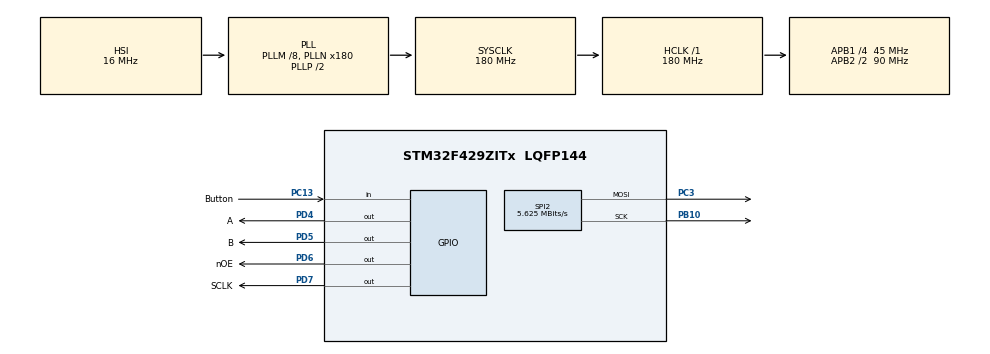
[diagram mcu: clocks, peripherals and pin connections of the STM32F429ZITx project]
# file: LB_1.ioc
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Mcu.Family=STM32F4
Mcu.Name=STM32F429ZITx
Mcu.Package=LQFP144
NVIC.PriorityGroup=NVIC_PRIORITYGROUP_4
NVIC.RCC_IRQn=true\:0\:0\:false\:false\:true\:true\:false\:true
NVIC.TIM1_UP_TIM10_IRQn=true\:0\:0\:false\:false\:true\:true\:true\:true
NVIC.TIM2_IRQn=true\:0\:0\:false\:false\:true\:true\:true\:true
PB10.Mode=TX_Only_Simplex_Unidirect_Master
PB10.Signal=SPI2_SCK
PC13.GPIO_Label=Button
PC13.Signal=GPIO_Input
PC14/OSC32_IN.Mode=LSE-External-Oscillator
PC14/OSC32_IN.Signal=RCC_OSC32_IN
PC15/OSC32_OUT.Mode=LSE-External-Oscillator
PC15/OSC32_OUT.Signal=RCC_OSC32_OUT
PC3.Mode=TX_Only_Simplex_Unidirect_Master
PC3.Signal=SPI2_MOSI
PD4.GPIO_Label=A
PD4.Signal=GPIO_Output
PD5.GPIO_Label=B
PD5.Signal=GPIO_Output
PD6.GPIO_Label=nOE
PD6.Signal=GPIO_Output
PD7.GPIO_Label=SCLK
PD7.Signal=GPIO_Output
PH0/OSC_IN.Mode=HSE-External-Oscillator
PH0/OSC_IN.Signal=RCC_OSC_IN
PH1/OSC_OUT.Mode=HSE-External-Oscillator
PH1/OSC_OUT.Signal=RCC_OSC_OUT
ProjectManager.HeapSize=0x200
ProjectManager.StackSize=0x400
ProjectManager.TargetToolchain=STM32CubeIDE
RCC.48MHZClocksFreq_Value=90000000
RCC.AHBFreq_Value=180000000
RCC.APB1CLKDivider=RCC_HCLK_DIV4
RCC.APB1Freq_Value=45000000
RCC.APB1TimFreq_Value=90000000
RCC.APB2CLKDivider=RCC_HCLK_DIV2
RCC.APB2Freq_Value=90000000
RCC.APB2TimFreq_Value=180000000
RCC.CortexFreq_Value=180000000
RCC.HCLKFreq_Value=180000000
RCC.HSE_VALUE=25000000
RCC.HSI_VALUE=16000000
RCC.PLLM=8
RCC.PLLN=180
RCC.SYSCLKFreq_VALUE=180000000
RCC.SYSCLKSource=RCC_SYSCLKSOURCE_PLLCLK
RCC.VCOOutputFreq_Value=360000000
SPI2.BaudRatePrescaler=SPI_BAUDRATEPRESCALER_8
SPI2.CalculateBaudRate=5.625 MBits/s
SPI2.Direction=SPI_DIRECTION_2LINES
SPI2.Mode=SPI_MODE_MASTER
SPI2.VirtualType=VM_MASTER
TIM1.Period=1000
TIM1.Prescaler=1000
TIM2.Period=1000
TIM2.Prescaler=1000
VP_TIM1_VS_ClockSourceINT.Mode=Internal
VP_TIM2_VS_ClockSourceINT.Mode=Internal
board=custom

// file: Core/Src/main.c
/* USER CODE BEGIN Header */
/**
  ******************************************************************************
  * @file           : main.c
  * @brief          : Main program body
  ******************************************************************************
  * @attention
  *
  * Copyright (c) 2023 STMicroelectronics.
  * All rights reserved.
  *
  * This software is licensed under terms that can be found in the LICENSE file
  * in the root directory of this software component.
  * If no LICENSE file comes with this software, it is provided AS-IS.
  *
  ******************************************************************************
  */
/* USER CODE END Header */
#include <frame.h>
#include "main.h"

SPI_HandleTypeDef hspi2;

TIM_HandleTypeDef htim1;
TIM_HandleTypeDef htim2;

void SystemClock_Config(void);
static void MX_GPIO_Init(void);
static void MX_TIM2_Init(void);
static void MX_TIM1_Init(void);
static void MX_SPI2_Init(void);

int main(void)
{
  /* USER CODE BEGIN 1 */
//  uint8_t pData = 0b11111110;

  /* USER CODE END 1 */

  /* MCU Configuration--------------------------------------------------------*/

  /* Reset of all peripherals, Initializes the Flash interface and the Systick. */
  HAL_Init();

  /* Configure the system clock */
  SystemClock_Config();

  /* Initialize all configured peripherals */
  MX_GPIO_Init();
  MX_TIM2_Init();
  MX_TIM1_Init();
  MX_SPI2_Init();

  /* Infinite loop */
  /* USER CODE BEGIN WHILE */
  uint8_t cadr_show = 0;
  uint8_t tek_state = 0;

  while(1){

	if((HAL_GPIO_ReadPin(Button_GPIO_Port, Button_Pin)) && (tek_state == 0)){
		cadr_show++;
		tek_state = 1;
		if (cadr_show == 9) {
			cadr_show = 1;
		}
	  }

	if(!(HAL_GPIO_ReadPin(Button_GPIO_Port, Button_Pin))){
		  tek_state = 0;}

	Output_Each_Frame(cadr_show);

  }
}

void SystemClock_Config(void)
{
  RCC_OscInitTypeDef RCC_OscInitStruct = {0};
  RCC_ClkInitTypeDef RCC_ClkInitStruct = {0};

  /** Configure the main internal regulator output voltage
  */
  __HAL_RCC_PWR_CLK_ENABLE();
  __HAL_PWR_VOLTAGESCALING_CONFIG(PWR_REGULATOR_VOLTAGE_SCALE1);

  /** Initializes the RCC Oscillators according to the specified parameters
  * in the RCC_OscInitTypeDef structure.
  */
  RCC_OscInitStruct.OscillatorType = RCC_OSCILLATORTYPE_HSI;
  RCC_OscInitStruct.HSIState = RCC_HSI_ON;
  RCC_OscInitStruct.HSICalibrationValue = RCC_HSICALIBRATION_DEFAULT;
  RCC_OscInitStruct.PLL.PLLState = RCC_PLL_ON;
  RCC_OscInitStruct.PLL.PLLSource = RCC_PLLSOURCE_HSI;
  RCC_OscInitStruct.PLL.PLLM = 8;
  RCC_OscInitStruct.PLL.PLLN = 180;
  RCC_OscInitStruct.PLL.PLLP = RCC_PLLP_DIV2;
  RCC_OscInitStruct.PLL.PLLQ = 4;
  if (HAL_RCC_OscConfig(&RCC_OscInitStruct) != HAL_OK)
  {
    Error_Handler();
  }

  /** Activate the Over-Drive mode
  */
  if (HAL_PWREx_EnableOverDrive() != HAL_OK)
  {
    Error_Handler();
  }

  /** Initializes the CPU, AHB and APB buses clocks
  */
  RCC_ClkInitStruct.ClockType = RCC_CLOCKTYPE_HCLK|RCC_CLOCKTYPE_SYSCLK
                              |RCC_CLOCKTYPE_PCLK1|RCC_CLOCKTYPE_PCLK2;
  RCC_ClkInitStruct.SYSCLKSource = RCC_SYSCLKSOURCE_PLLCLK;
  RCC_ClkInitStruct.AHBCLKDivider = RCC_SYSCLK_DIV1;
  RCC_ClkInitStruct.APB1CLKDivider = RCC_HCLK_DIV4;
  RCC_ClkInitStruct.APB2CLKDivider = RCC_HCLK_DIV2;

  if (HAL_RCC_ClockConfig(&RCC_ClkInitStruct, FLASH_LATENCY_5) != HAL_OK)
  {
    Error_Handler();
  }
}

static void MX_SPI2_Init(void)
{

  /* SPI2 parameter configuration*/
  hspi2.Instance = SPI2;
  hspi2.Init.Mode = SPI_MODE_MASTER;
  hspi2.Init.Direction = SPI_DIRECTION_2LINES;
  hspi2.Init.DataSize = SPI_DATASIZE_8BIT;
  hspi2.Init.CLKPolarity = SPI_POLARITY_LOW;
  hspi2.Init.CLKPhase = SPI_PHASE_1EDGE;
  hspi2.Init.NSS = SPI_NSS_SOFT;
  hspi2.Init.BaudRatePrescaler = SPI_BAUDRATEPRESCALER_8;
  hspi2.Init.FirstBit = SPI_FIRSTBIT_MSB;
  hspi2.Init.TIMode = SPI_TIMODE_DISABLE;
  hspi2.Init.CRCCalculation = SPI_CRCCALCULATION_DISABLE;
  hspi2.Init.CRCPolynomial = 10;
  if (HAL_SPI_Init(&hspi2) != HAL_OK)
  {
    Error_Handler();
  }

}

static void MX_TIM1_Init(void)
{

  TIM_ClockConfigTypeDef sClockSourceConfig = {0};
  TIM_MasterConfigTypeDef sMasterConfig = {0};

  htim1.Instance = TIM1;
  htim1.Init.Prescaler = 1000;
  htim1.Init.CounterMode = TIM_COUNTERMODE_UP;
  htim1.Init.Period = 1000;
  htim1.Init.ClockDivision = TIM_CLOCKDIVISION_DIV1;
  htim1.Init.RepetitionCounter = 0;
  htim1.Init.AutoReloadPreload = TIM_AUTORELOAD_PRELOAD_DISABLE;
  if (HAL_TIM_Base_Init(&htim1) != HAL_OK)
  {
    Error_Handler();
  }
  sClockSourceConfig.ClockSource = TIM_CLOCKSOURCE_INTERNAL;
  if (HAL_TIM_ConfigClockSource(&htim1, &sClockSourceConfig) != HAL_OK)
  {
    Error_Handler();
  }
  sMasterConfig.MasterOutputTrigger = TIM_TRGO_RESET;
  sMasterConfig.MasterSlaveMode = TIM_MASTERSLAVEMODE_DISABLE;
  if (HAL_TIMEx_MasterConfigSynchronization(&htim1, &sMasterConfig) != HAL_OK)
  {
    Error_Handler();
  }

}

static void MX_TIM2_Init(void)
{

  TIM_ClockConfigTypeDef sClockSourceConfig = {0};
  TIM_MasterConfigTypeDef sMasterConfig = {0};

  htim2.Instance = TIM2;
  htim2.Init.Prescaler = 1000;
  htim2.Init.CounterMode = TIM_COUNTERMODE_UP;
  htim2.Init.Period = 1000;
  htim2.Init.ClockDivision = TIM_CLOCKDIVISION_DIV1;
  htim2.Init.AutoReloadPreload = TIM_AUTORELOAD_PRELOAD_DISABLE;
  if (HAL_TIM_Base_Init(&htim2) != HAL_OK)
  {
    Error_Handler();
  }
  sClockSourceConfig.ClockSource = TIM_CLOCKSOURCE_INTERNAL;
  if (HAL_TIM_ConfigClockSource(&htim2, &sClockSourceConfig) != HAL_OK)
  {
    Error_Handler();
  }
  sMasterConfig.MasterOutputTrigger = TIM_TRGO_RESET;
  sMasterConfig.MasterSlaveMode = TIM_MASTERSLAVEMODE_DISABLE;
  if (HAL_TIMEx_MasterConfigSynchronization(&htim2, &sMasterConfig) != HAL_OK)
  {
    Error_Handler();
  }

}

static void MX_GPIO_Init(void)
{
  GPIO_InitTypeDef GPIO_InitStruct = {0};

  /* GPIO Ports Clock Enable */
  __HAL_RCC_GPIOC_CLK_ENABLE();
  __HAL_RCC_GPIOH_CLK_ENABLE();
  __HAL_RCC_GPIOB_CLK_ENABLE();
  __HAL_RCC_GPIOD_CLK_ENABLE();

  /*Configure GPIO pin Output Level */
  HAL_GPIO_WritePin(GPIOD, A_Pin|B_Pin|nOE_Pin|SCLK_Pin, GPIO_PIN_RESET);

  /*Configure GPIO pin : Button_Pin */
  GPIO_InitStruct.Pin = Button_Pin;
  GPIO_InitStruct.Mode = GPIO_MODE_INPUT;
  GPIO_InitStruct.Pull = GPIO_NOPULL;
  HAL_GPIO_Init(Button_GPIO_Port, &GPIO_InitStruct);

  /*Configure GPIO pins : A_Pin B_Pin nOE_Pin SCLK_Pin */
  GPIO_InitStruct.Pin = A_Pin|B_Pin|nOE_Pin|SCLK_Pin;
  GPIO_InitStruct.Mode = GPIO_MODE_OUTPUT_PP;
  GPIO_InitStruct.Pull = GPIO_NOPULL;
  GPIO_InitStruct.Speed = GPIO_SPEED_FREQ_LOW;
  HAL_GPIO_Init(GPIOD, &GPIO_InitStruct);

}

void Error_Handler(void)
{
  __disable_irq();
  while (1)
  {
  }
}
